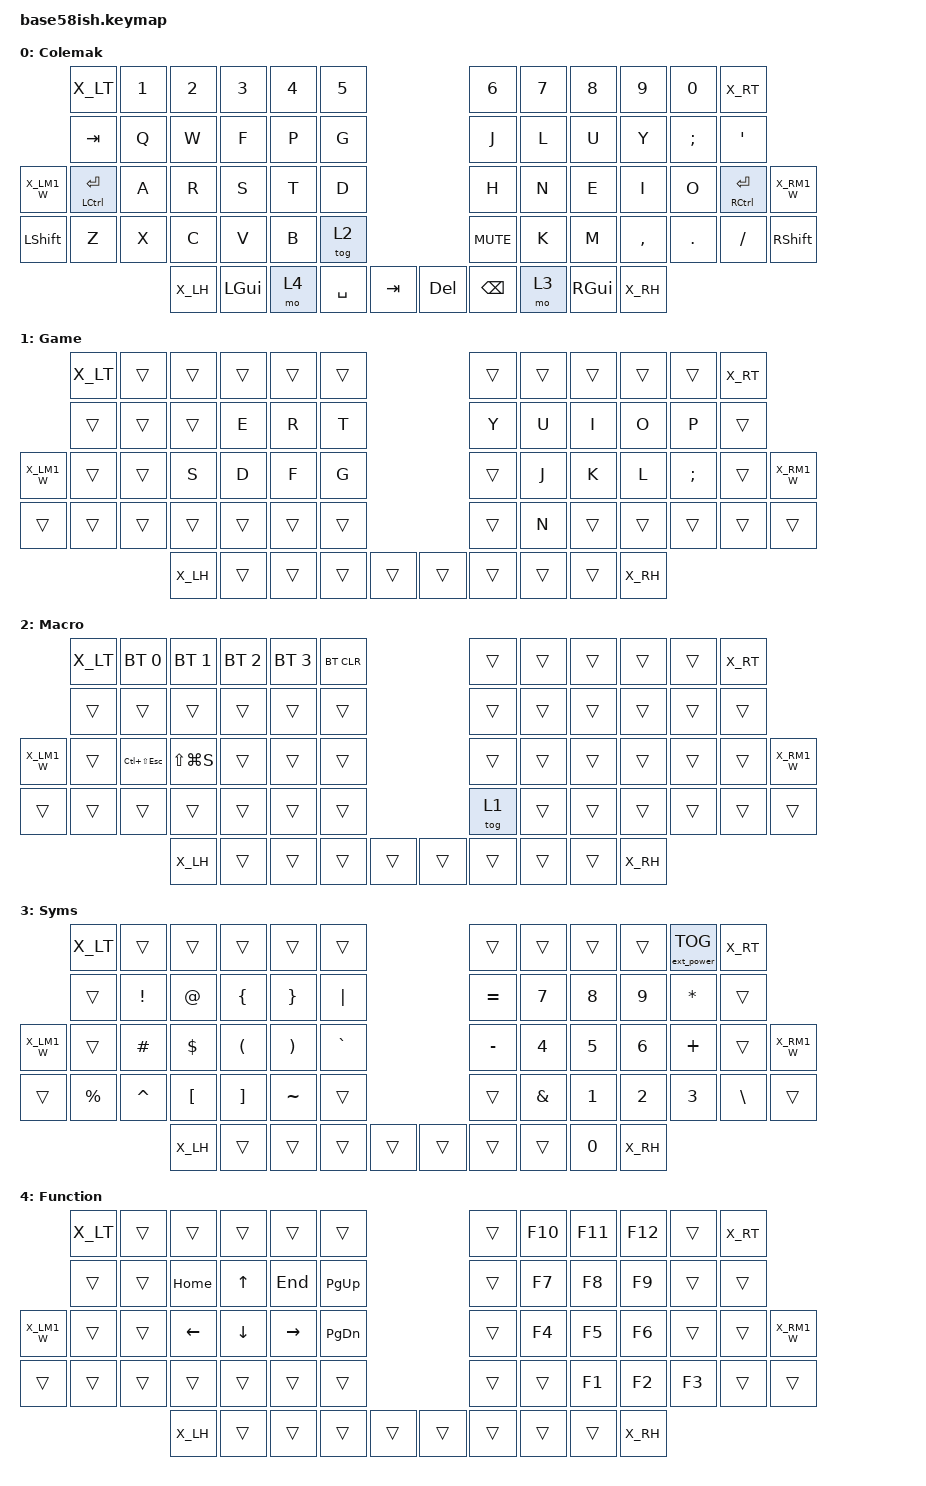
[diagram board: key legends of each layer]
#include "zmk-helpers/helper.h"
#include "zmk-helpers/key-labels/lily58.h"
#include <behaviors.dtsi>
#include <dt-bindings/zmk/bt.h>
#include <dt-bindings/zmk/ext_power.h>
#include <dt-bindings/zmk/keys.h>

// Define tapping terms

#if !defined HM_TAPPING_TERM
    #define HM_TAPPING_TERM 300
#endif
#if !defined HM_TAPPING_TERM_FAST
    #define HM_TAPPING_TERM_FAST 200
#endif
#if !defined HM_PRIOR_IDLE
    #define HM_PRIOR_IDLE 150
#endif

// Define keys

#if !defined KEYS_L
    #define KEYS_L LT0 LT1 LT2 LT3 LT4 LT5 LM0 LM1 LM2 LM3 LM4 LM5 LB0 LB1 LB2 LB3 LB4 LB5
#endif
#if !defined KEYS_R
    #define KEYS_R RT0 RT1 RT2 RT3 RT4 RT5 RM0 RM1 RM2 RM3 RM4 RM5 RB0 RB1 RB2 RB3 RB4 RB5
#endif
#if !defined KEYS_T
    #define KEYS_T LH3 LH2 LH1 LH0 RH0 RH1 RH2 RH3
#endif

#if !defined X_LT 
    #define X_LT
#endif

#if !defined X_LM1_W 
    #define X_LM1_W
#endif

#if !defined X_LH
    #define X_LH
#endif

#if !defined X_RT 
    #define X_RT
#endif

#if !defined X_RM1_W 
    #define X_RM1_W
#endif

#if !defined X_RH
    #define X_RH
#endif

/ {
    behaviors {
        // Positional Homerow mods
        // Homerow mods that prevent accidental activations when rolling keys,
        // such as when typing `st` or `ne` on colemak-dh layouts or `as` on
        // qwerty.
        //
        // Works by only allowing a mod to activate within tapping-term if
        // it's on the opposite side of the keyboard or on the same side thumb
        // keys.
        // Further optimization using urob's timerless homerow mods method:
        // https://github.com/urob/zmk-config#timeless-homerow-mods

        hm_l: homerow_mods_left {
            compatible = "zmk,behavior-hold-tap";
            #binding-cells = <2>;
            bindings = <&kp>, <&kp>;

            flavor = "balanced";
            tapping-term-ms = <HM_TAPPING_TERM>;
            quick-tap-ms = <175>;                // repeat on tap-into-hold
            require-prior-idle-ms = <HM_PRIOR_IDLE>;
            hold-trigger-key-positions = <KEYS_R KEYS_T>;
            hold-trigger-on-release;
        };

        hm_r: homerow_mods_right {
            compatible = "zmk,behavior-hold-tap";
            #binding-cells = <2>;
            bindings = <&kp>, <&kp>;

            flavor = "balanced";
            tapping-term-ms = <HM_TAPPING_TERM>;
            quick-tap-ms = <175>;
            require-prior-idle-ms = <HM_PRIOR_IDLE>;
            hold-trigger-key-positions = <KEYS_L KEYS_T>;
            hold-trigger-on-release;
        };

        // Positional Homerow mods for shift
        // Use faster tapping term and disable some features that may
        // cause false negatives.

        hm_shift_l: hm_shift_l {
            compatible = "zmk,behavior-hold-tap";
            #binding-cells = <2>;
            bindings = <&kp>, <&kp>;

            flavor = "balanced";
            tapping-term-ms = <HM_TAPPING_TERM_FAST>;
            quick-tap-ms = <175>;
            require-prior-idle-ms = <HM_PRIOR_IDLE>;
            hold-trigger-key-positions = <KEYS_R KEYS_T>;

            // hold-trigger-on-release;
        };

        hm_shift_r: hm_shift_r {
            compatible = "zmk,behavior-hold-tap";
            #binding-cells = <2>;
            bindings = <&kp>, <&kp>;

            flavor = "balanced";
            tapping-term-ms = <HM_TAPPING_TERM_FAST>;
            quick-tap-ms = <175>;
            require-prior-idle-ms = <HM_PRIOR_IDLE>;
            hold-trigger-key-positions = <KEYS_L KEYS_T>;

            // hold-trigger-on-release;
        };

        /*
         * Non-Positional Homerow Mods
         * Used for &mm_grescm_gui behavior on left hand.
         *
         * Usage: &hm LSHFT T
         * Tap: T
         * Tap-Tap-Hold: Repeat T
         * Hold: LSHIFT
         */

        hm: homerow_mods {
            compatible = "zmk,behavior-hold-tap";
            #binding-cells = <2>;
            bindings = <&kp>, <&kp>;

            flavor = "balanced";
            tapping-term-ms = <HM_TAPPING_TERM>;
            quick-tap-ms = <200>;
        };
    };
};

/ {
    keymap {
        compatible = "zmk,keymap";

        colemak {
            display-name = "Colemak";
            bindings = <
        X_LT             &kp N1         &kp N2         &kp N3        &kp N4        &kp N5                                  &kp N6         &kp N7        &kp N8        &kp N9         &kp N0    X_RT
        &kp TAB          &kp Q          &kp W          &kp F         &kp P         &kp G                                   &kp J          &kp L         &kp U         &kp Y          &kp SEMI  &kp SQT
X_LM1_W &mt LCTRL ENTER  &kp A          &kp R          &kp S         &kp T         &kp D                                   &kp H          &kp N         &kp E         &kp I          &kp O     &mt RCTRL ENTER  X_RM1_W
        &kp LSHFT        &kp Z          &kp X          &kp C         &kp V         &kp B      &tog 2        &kp C_MUTE     &kp K          &kp M         &kp COMMA     &kp DOT        &kp FSLH  &kp RSHFT
                                        X_LH           &kp LGUI      &mo 4         &kp SPACE  &kp TAB       &kp DEL        &kp BACKSPACE  &mo 3         &kp RGUI      X_RH
            >;

            sensor-bindings = <&inc_dec_kp LC(Y) LC(Z) &inc_dec_kp C_VOL_DN C_VOL_UP>;
        };

        game {
            display-name = "Game";
            bindings = <
        X_LT    &trans  &trans  &trans  &trans  &trans                    &trans  &trans  &trans  &trans  &trans    X_RT
        &trans  &trans  &trans  &kp E   &kp R   &kp T                     &kp Y   &kp U   &kp I   &kp O   &kp P     &trans
X_LM1_W &trans  &trans  &kp S   &kp D   &kp F   &kp G                     &trans  &kp J   &kp K   &kp L   &kp SEMI  &trans  X_RM1_W
        &trans  &trans  &trans  &trans  &trans  &trans  &trans    &trans  &kp N   &trans  &trans  &trans  &trans    &trans
                        X_LH    &trans  &trans  &trans  &trans    &trans  &trans  &trans  &trans  X_RH
            >;
        };

        macro {
            display-name = "Macro";
            bindings = <
        X_LT         &bt BT_SEL 0        &bt BT_SEL 1   &bt BT_SEL 2  &bt BT_SEL 3  &bt BT_CLR                       &trans  &trans  &trans  &trans  &trans  X_RT
        &trans       &trans              &trans         &trans        &trans        &trans                           &trans  &trans  &trans  &trans  &trans  &trans
X_LM1_W &trans       &kp LC(LS(ESCAPE))  &kp LS(LG(S))  &trans        &trans        &trans                           &trans  &trans  &trans  &trans  &trans  &trans  X_RM1_W
        &trans       &trans              &trans         &trans        &trans        &trans      &trans    &tog 1     &trans  &trans  &trans  &trans  &trans  &trans
                                         X_LH           &trans        &trans        &trans      &trans    &trans     &trans  &trans  &trans  X_RH
            >;
        };

        symbol {
            display-name = "Syms";
            bindings = <
        X_LT    &trans     &trans     &trans    &trans    &trans                       &trans     &trans  &trans  &trans   &ext_power EP_TOG  X_RT
        &trans  &kp EXCL   &kp AT     &kp LBRC  &kp RBRC  &kp PIPE                     &kp EQUAL  &kp N7  &kp N8  &kp N9   &kp ASTRK          &trans
X_LM1_W &trans  &kp HASH   &kp DLLR   &kp LPAR  &kp RPAR  &kp GRAVE                    &kp MINUS  &kp N4  &kp N5  &kp N6   &kp PLUS           &trans  X_RM1_W
        &trans  &kp PRCNT  &kp CARET  &kp LBKT  &kp RBKT  &kp TILDE  &trans    &trans  &kp AMPS   &kp N1  &kp N2  &kp N3   &kp BSLH           &trans
                           X_LH       &trans    &trans    &trans     &trans    &trans  &trans     &trans  &kp N0  X_RH
            >;
        };

        function {
            display-name = "Function";
            bindings = <
        X_LT    &trans  &trans    &trans    &trans     &trans                       &trans  &kp F10  &kp F11  &kp F12  &trans  X_RT
        &trans  &trans  &kp HOME  &kp UP    &kp END    &kp PG_UP                    &trans  &kp F7   &kp F8   &kp F9   &trans  &trans
X_LM1_W &trans  &trans  &kp LEFT  &kp DOWN  &kp RIGHT  &kp PG_DN                    &trans  &kp F4   &kp F5   &kp F6   &trans  &trans  X_RM1_W
        &trans  &trans  &trans    &trans    &trans     &trans     &trans    &trans  &trans  &kp F1   &kp F2   &kp F3   &trans  &trans
                        X_LH      &trans    &trans     &trans     &trans    &trans  &trans  &trans   &trans   X_RH
            >;
        };
    };
};
